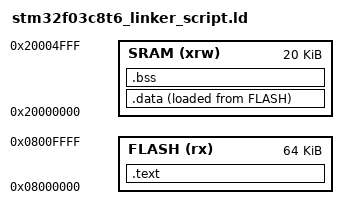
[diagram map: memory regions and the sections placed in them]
ENTRY(Reset_Handler)

_estack = ORIGIN(SRAM) + LENGTH(RAM);

MEMORY
{
  SRAM    (xrw)    : ORIGIN = 0x20000000,   LENGTH = 20K
  FLASH    (rx)    : ORIGIN = 0x8000000,   LENGTH = 64K
}

SECTIONS
{
    .text :
    {
        . = ALIGN(4);
        KEEP(*(.isr_vector))
        *(.isr_vector)
        *(.text)
        *(.text.*)
        *(.init)
        *(.fini)
        *(.rodata)
        *(.rodata.*)
        . = ALIGN(4);
        _etext = .;
    }> FLASH

    _la_data = LOADADDR(.data);

    .data :
    {
        . = ALIGN(4);
        _sdata = .;
        *(.data)
        *(.data.*)
        . = ALIGN(4);
        _edata = .;
    }> SRAM AT> FLASH

    .bss :
    {
        . = ALIGN(4);
        _sbss = .;
        __bss_start__ = _sbss;
        *(.bss)
        *(.bss.*)
        *(COMMON)
        . = ALIGN(4);
        _ebss = .;
        __bss_end__ = _ebss;
        . = ALIGN(4);
        end = .;
        __end__ = .;
    }> SRAM

}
